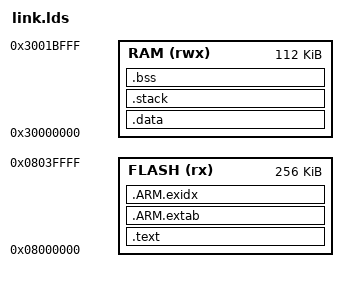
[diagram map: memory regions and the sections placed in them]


/*
 *-------- <<< Use Configuration Wizard in Context Menu >>> -------------------
 */

/*---------------------- Flash Configuration ----------------------------------
  <h> Flash Configuration
    <o0> Flash Base Address <0x0-0xFFFFFFFF:8>
    <o1> Flash Size (in Bytes) <0x0-0xFFFFFFFF:8>
  </h>
  -----------------------------------------------------------------------------*/
__ROM_BASE = 0x08000000;
__ROM_SIZE = 0x00040000;

/*--------------------- Embedded RAM Configuration ----------------------------
  <h> RAM Configuration
    <o0> RAM Base Address    <0x0-0xFFFFFFFF:8>
    <o1> RAM Size (in Bytes) <0x0-0xFFFFFFFF:8>
  </h>
 -----------------------------------------------------------------------------*/
__RAM_BASE = 0x30000000;
__RAM_SIZE = 0x0001C000;

/*--------------------- Stack / Heap Configuration ----------------------------
  <h> Stack / Heap Configuration
    <o0> Stack Size (in Bytes) <0x0-0xFFFFFFFF:8>
    <o1> Heap Size (in Bytes) <0x0-0xFFFFFFFF:8>
  </h>
  -----------------------------------------------------------------------------*/
__STACK_SIZE = 0x00001000;
/*__HEAP_SIZE  = 0x00001000;*/

/*
 *-------------------- <<< end of configuration section >>> -------------------
 */

/* ARMv8-M stack sealing:
   to use ARMv8-M stack sealing set __STACKSEAL_SIZE to 8 otherwise keep 0
 */
__STACKSEAL_SIZE = 0;


MEMORY
{
  FLASH (rx)  : ORIGIN = __ROM_BASE, LENGTH = __ROM_SIZE
  RAM   (rwx) : ORIGIN = __RAM_BASE, LENGTH = __RAM_SIZE
}

/* Linker script to place sections and symbol values. Should be used together
 * with other linker script that defines memory regions FLASH and RAM.
 * It references following symbols, which must be defined in code:
 *   Reset_Handler : Entry of reset handler
 *
 * It defines following symbols, which code can use without definition:
 *   __exidx_start
 *   __exidx_end
 *   __copy_table_start__
 *   __copy_table_end__
 *   __zero_table_start__
 *   __zero_table_end__
 *   __etext
 *   __data_start__
 *   __preinit_array_start
 *   __preinit_array_end
 *   __init_array_start
 *   __init_array_end
 *   __fini_array_start
 *   __fini_array_end
 *   __data_end__
 *   __bss_start__
 *   __bss_end__
 *   __end__
 *   end
 *   __HeapLimit
 *   __StackLimit
 *   __StackTop
 *   __stack
 *   __StackSeal      (only if ARMv8-M stack sealing is used)
 */
ENTRY(Reset_Handler)

SECTIONS
{
  .text :
  {
    . = ALIGN(4);
    KEEP(*(.vectors))
    . = ALIGN(4);
    *(.text)                        /* remaining code */
    *(.text.*)                      /* remaining code */
    *(.rodata)                      /* read-only data (constants) */
    *(.rodata*)
    *(.glue_7)
    *(.glue_7t)
    *(.gnu.linkonce.t*)

    /* section information for finsh shell */
    . = ALIGN(4);
    __fsymtab_start = .;
    KEEP(*(FSymTab))
    __fsymtab_end = .;

    . = ALIGN(4);
    __vsymtab_start = .;
    KEEP(*(VSymTab))
    __vsymtab_end = .;

    /* section information for initial. */
    . = ALIGN(4);
    __rt_init_start = .;
    KEEP(*(SORT(.rti_fn*)))
    __rt_init_end = .;

    . = ALIGN(4);

    PROVIDE(__ctors_start__ = .);
    KEEP (*(SORT(.init_array.*)))
    KEEP (*(.init_array))
    PROVIDE(__ctors_end__ = .);

    . = ALIGN(4);

    _etext = .;
  } > FLASH

  /*
   * SG veneers:
   * All SG veneers are placed in the special output section .gnu.sgstubs. Its start address
   * must be set, either with the command line option ��--section-start�� or in a linker script,
   * to indicate where to place these veneers in memory.
   */
/*
  .gnu.sgstubs :
  {
    . = ALIGN(32);
  } > FLASH
*/
  .ARM.extab :
  {
    *(.ARM.extab* .gnu.linkonce.armextab.*)
  } > FLASH

  __exidx_start = .;
  .ARM.exidx :
  {
    *(.ARM.exidx* .gnu.linkonce.armexidx.*)

    /* This is used by the startup in order to initialize the .data secion */
    _sidata = .;
  } > FLASH
  __exidx_end = .;

   __etext = ALIGN (4);

  .data : AT (__etext)
  {
    . = ALIGN(4);
    /* This is used by the startup in order to initialize the .data secion */
     _sdata = . ;

     *(.data)
     *(.data.*)
     *(.gnu.linkonce.d*)

     PROVIDE(__dtors_start__ = .);
     KEEP(*(SORT(.dtors.*)))
     KEEP(*(.dtors))
     PROVIDE(__dtors_end__ = .);

     . = ALIGN(4);
     /* This is used by the startup in order to initialize the .data secion */
     _edata = . ;

  } > RAM

  /*
   * Secondary data section, optional
   *
   * Remember to add each additional data section
   * to the .copy.table above to asure proper
   * initialization during startup.
   */
/*
  __etext2 = ALIGN (4);

  .data2 : AT (__etext2)
  {
    . = ALIGN(4);
    __data2_start__ = .;
    *(.data2)
    *(.data2.*)
    . = ALIGN(4);
    __data2_end__ = .;

  } > RAM2
*/

/*
  .heap (COPY) :
  {
    . = ALIGN(8);
    __end__ = .;
    PROVIDE(end = .);
    . = . + __HEAP_SIZE;
    . = ALIGN(8);
    __HeapLimit = .;
  } > RAM
  */


  /* ARMv8-M stack sealing:
     to use ARMv8-M stack sealing uncomment '.stackseal' section
   */
/*
  .stackseal :
  {
    . = ALIGN(8);
    __StackSeal = .;
    . = . + 8;
    . = ALIGN(8);
  } > RAM
*/

  .stack :
  {
    . = ALIGN(8);
    _sstack = .;
    . = . + __STACK_SIZE;
    . = ALIGN(8);
    _estack = .;
  } > RAM

  __bss_start__ = .;
  .bss :
  {
    . = ALIGN(4);
    _sbss = .;

    *(.bss)
    *(.bss.*)
    *(COMMON)
    . = ALIGN(4);
     _ebss = . ;

     *(.bss.init)
  } > RAM
  __bss_end__ = .;

  /*
   * Secondary bss section, optional
   *
   * Remember to add each additional bss section
   * to the .zero.table above to asure proper
   * initialization during startup.
   */
/*
  .bss2 :
  {
    . = ALIGN(4);
    __bss2_start__ = .;
    *(.bss2)
    *(.bss2.*)
    . = ALIGN(4);
    __bss2_end__ = .;
  } > RAM2 AT > RAM2
*/
}
